# dmpac_targetdb register map
Vendor: Texas Instruments
Registers are 32-bit, read-write, no defined reset value unless marked. A register's access mark holds for its fields unless they carry their own. Offsets are as the file gives them; [hi:lo] are bit positions; {n}, {i} and the like mark numbered series; 'fields as' and 'values as' point back to an identical list.

## DMPAC (part 4 of 5) — Depth and Motion Perception Accelerator (DMPAC)
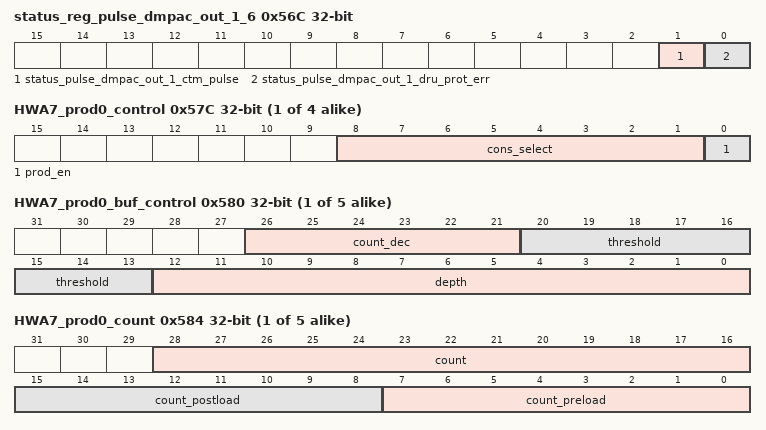
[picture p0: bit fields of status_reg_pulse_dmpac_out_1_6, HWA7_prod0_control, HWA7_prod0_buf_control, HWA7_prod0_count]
0x56C status_reg_pulse_dmpac_out_1_6 — Status Register 27
  [1] status_pulse_dmpac_out_1_ctm_pulse — Status ,write 1 to set, for pulse_dmpac_out_1_en_ctm_pulse
  [0] status_pulse_dmpac_out_1_dru_prot_err — Status ,write 1 to set, for pulse_dmpac_out_1_en_dru_prot_err
{0x57C+0x14*i} HWA7_prod{i}_control (i=0..3) — Controlling producer socket{i} for HWA7
  [8:1] cons_select — consumer select for HWA7 prod socket {i}. Used in decrementing count of producer buffer
  [0] prod_en — '1' -> Producer socket 0 enable , '0' Disable
{0x580+0x14*i} HWA7_prod{i}_buf_control (i=0..4) — Controlling producer socket{i} buffer for HWA7
  [26:21] count_dec — Count decrement value for prod count
  [20:13] threshold — Count threshold to generate pend for consumer
  [12:0] depth — Maximum number of producer buffer count
{0x584+0x14*i} HWA7_prod{i}_count access per field (i=0..4) — Defining count values for pre/post load for generating pend by HWA7 prod{i}
  [28:16] count ro — current count value
  [15:8] count_postload rw — count postload after producer max thread count reached
  [7:0] count_preload rw — count preload after scheduler start/init
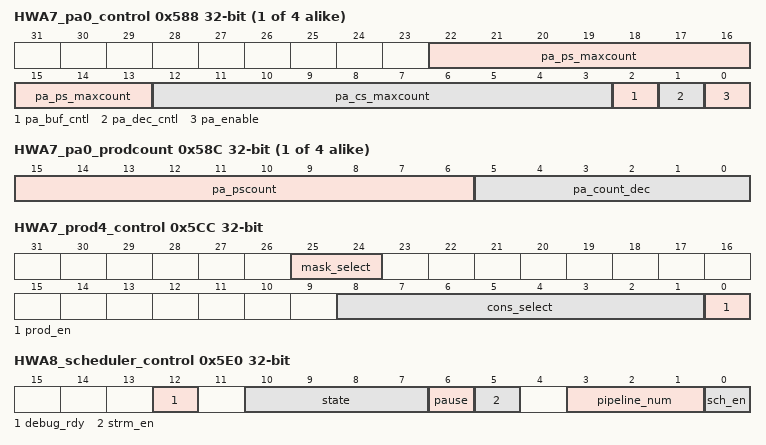
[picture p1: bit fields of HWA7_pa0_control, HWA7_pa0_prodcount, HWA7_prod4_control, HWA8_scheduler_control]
{0x588+0x14*i} HWA7_pa{i}_control (i=0..3) — control register to manage pattern adapter on HWA7 prod socket{i}
  [22:13] pa_ps_maxcount — destination count for pattern adaptation (N), M --> N
  [12:3] pa_cs_maxcount — source count for pattern adaptation (M), M --> N
  [2] pa_buf_cntl — '1' -> Apply threshold, count_preload and count_postload on pattern adapter count (use this only when pa_enable='1') '0' -> Apply threshold, count_preload and count_postload on prod count (same behavior as if no pattern adapter. Note when pa_enable='1' and pa_buf_cntl='0' threshold is not used and ignored)
  [1] pa_dec_cntl — '1' -> post pattern adaptation, decrement ps count by count_dec , '0' -> post pattern adaptation, decrement ps count by pa_cs_maxcount
  [0] pa_enable — '1' -> pa enable, '0' -> disable
{0x58C+0x14*i} HWA7_pa{i}_prodcount access per field (i=0..3) — count values for HWA7 prod socket{i}
  [15:6] pa_pscount ro — current count value of pa prod count
  [5:0] pa_count_dec rw — Decrement count value of pa_prod_count after pattern adapter prod count reaches threshold
0x5CC HWA7_prod4_control — Controlling producer socket4 for HWA7
  [25:24] mask_select — define which tdone_mask apply to prod socket 4. tdone_mask[mask_select] applies to prod_socket4
  [8:1] cons_select — consumer select for HWA7 prod socket 4. Used in decrementing count of producer buffer
  [0] prod_en — '1' -> Producer socket 0 enable , '0' Disable
0x5E0 HWA8_scheduler_control access per field — Scheduler Control Register
  [12] debug_rdy rw — '0' -> HWA8 Scheduler resources must not be read during halted state. '1'-> HWA8 Scheduler resources are readable during halted state
  [10:7] state ro — Current state of HWA8 Scheduler
  [6] pause rw — '1' -> pause/suspend scheduler , '0' -> resume scheduler
  [5] strm_en rw — '1' -> Streaming input enable, '0' No streaming input
  [3:1] pipeline_num rw — Pipeline Number of HWA8 Scheduler
  [0] sch_en rw — scheduler enable; write '1' to enable scheduler
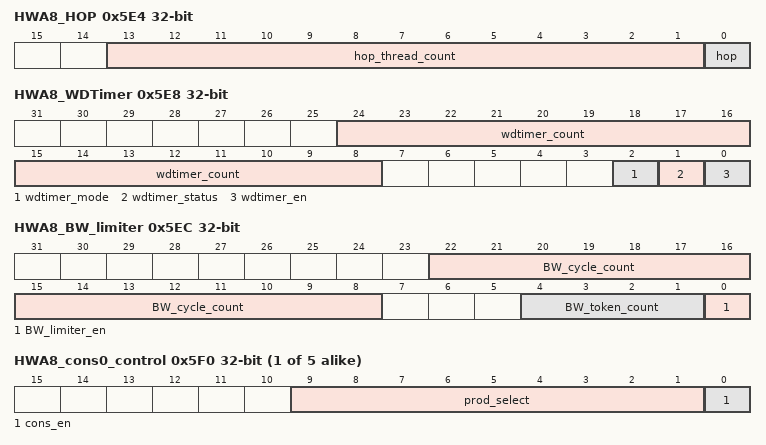
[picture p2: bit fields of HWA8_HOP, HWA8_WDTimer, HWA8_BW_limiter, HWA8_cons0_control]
0x5E4 HWA8_HOP — Scheduler HOP Control Register. Help in detecting eop within scheduler. Once configured, it counts task/channel starts and stops issuing further start. Specifically useful for Head of pipe dma scheduler .
  [13:1] hop_thread_count — Number of Task count for Head of pipe
  [0] hop — '1' -> Head of Pipe producer Sch , '0' -> No hop
0x5E8 HWA8_WDTimer access per field — Watchdog timer control register
  [24:8] wdtimer_count ro — Current value of HWA8 Scheduler watchdog timer count
  [2] wdtimer_mode rw — Watchdog timeout count '1' -> 128K , '0' -> 64K
  [1] wdtimer_status ro — HWA8 Scheduler watchdog timer status '1' -> Timer Active '0' -> Timer Inactive (count is stable)
  [0] wdtimer_en rw — '1' -> activate watchdog timer for 64K VPAC/DMPAC cycles between task start and task done '0' -> Disable watchdog timer
0x5EC HWA8_BW_limiter — Scheduler BW Control Register. Processing unit level BW control. Use DMA to eliminate peak system BW within processing units line/Block
  [22:8] BW_cycle_count — Average Cycle count between successive Task Start
  [4:1] BW_token_count — Max Token count to create average BW
  [0] BW_limiter_en — '1' -> Enable BW limiter function for HWA8 sch, '0' --> Disable
{0x5F0+4i} HWA8_cons{i}_control (i=0..4) — Controlling consumer socket {i} for HWA8
  [9:1] prod_select — producer select for HWA8 cons socket {i}
  [0] cons_en — '1' -> Consumer socket {i} enable , '0' Disable
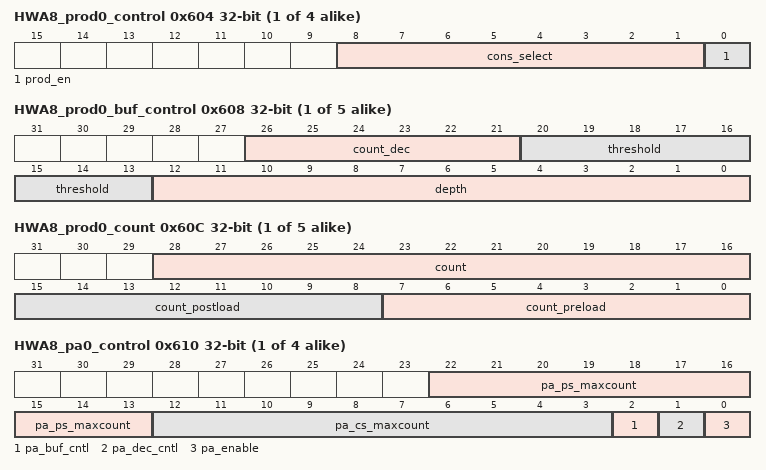
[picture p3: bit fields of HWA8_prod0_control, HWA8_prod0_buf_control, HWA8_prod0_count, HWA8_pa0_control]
{0x604+0x14*i} HWA8_prod{i}_control (i=0..3) — Controlling producer socket{i} for HWA8
  [8:1] cons_select — consumer select for HWA8 prod socket {i}. Used in decrementing count of producer buffer
  [0] prod_en — '1' -> Producer socket 0 enable , '0' Disable
{0x608+0x14*i} HWA8_prod{i}_buf_control (i=0..4) — Controlling producer socket{i} buffer for HWA8
  fields as HWA7_prod0_buf_control
{0x60C+0x14*i} HWA8_prod{i}_count access per field (i=0..4) — Defining count values for pre/post load for generating pend by HWA8 prod{i}
  fields as HWA7_prod0_count
{0x610+0x14*i} HWA8_pa{i}_control (i=0..3) — control register to manage pattern adapter on HWA8 prod socket{i}
  fields as HWA7_pa0_control
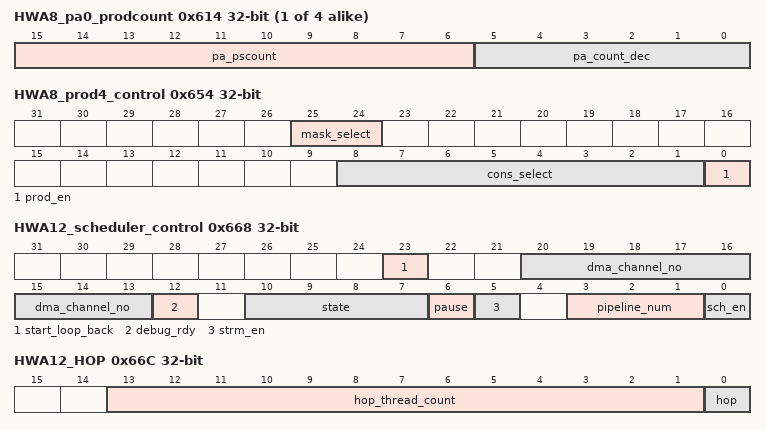
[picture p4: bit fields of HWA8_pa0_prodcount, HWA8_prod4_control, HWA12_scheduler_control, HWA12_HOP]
{0x614+0x14*i} HWA8_pa{i}_prodcount access per field (i=0..3) — count values for HWA8 prod socket{i}
  fields as HWA7_pa0_prodcount
0x654 HWA8_prod4_control — Controlling producer socket4 for HWA8
  [25:24] mask_select — define which tdone_mask apply to prod socket 4. tdone_mask[mask_select] applies to prod_socket4
  [8:1] cons_select — consumer select for HWA8 prod socket 4. Used in decrementing count of producer buffer
  [0] prod_en — '1' -> Producer socket 0 enable , '0' Disable
0x668 HWA12_scheduler_control access per field — Scheduler Control Register
  [23] start_loop_back rw — '1' -> loop back start onto done in same cycle w/o asserting external channel start, '0' No loop back
  [20:13] dma_channel_no rw — DMA channel number for thread scheduler for HWA12
  [12] debug_rdy rw — '0' -> HWA12 Scheduler resources must not be read during halted state. '1'-> HWA12 Scheduler resources are readable during halted state
  [10:7] state ro — Current state of HWA12 Scheduler
  [6] pause rw — '1' -> pause/suspend scheduler , '0' -> resume scheduler
  [5] strm_en rw — '1' -> Streaming input enable, '0' No streaming input
  [3:1] pipeline_num rw — Pipeline Number of HWA12 Scheduler
  [0] sch_en rw — scheduler enable; write '1' to enable scheduler
0x66C HWA12_HOP — Scheduler HOP Control Register. Help in detecting eop within scheduler. Once configured, it counts task/channel starts and stops issuing further starts. Specifically useful for Head of pipe dma scheduler .
  fields as HWA8_HOP
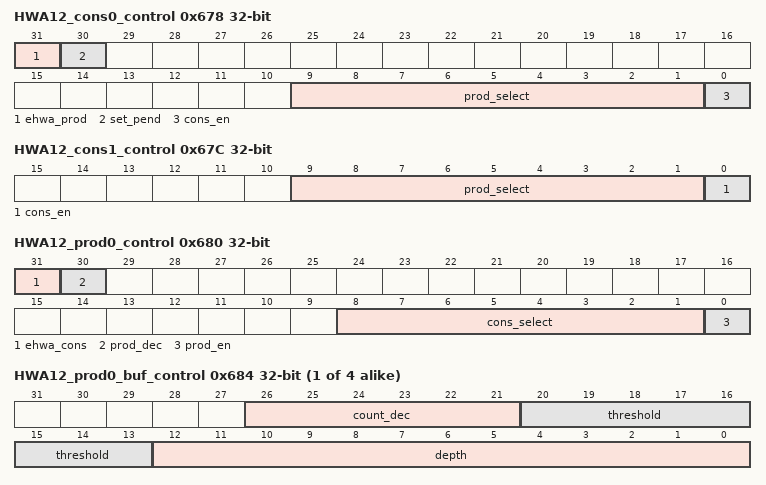
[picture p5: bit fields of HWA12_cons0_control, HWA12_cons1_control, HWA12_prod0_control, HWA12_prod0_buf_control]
0x678 HWA12_cons0_control access per field — Controlling consumer socket 0 for HWA12
  [31] ehwa_prod rw — '1' -> spare consumer is connected to external host producer , '0' --> no external host producer
  [30] set_pend wo — writing '1' sets pend on consumer socket
  [9:1] prod_select rw — producer select for HWA12 cons socket 0
  [0] cons_en rw — '1' -> Consumer socket 0 enable , '0' Disable
0x67C HWA12_cons1_control — Controlling consumer socket 1 for HWA12
  [9:1] prod_select — producer select for HWA12 cons socket 1
  [0] cons_en — '1' -> Consumer socket 1 enable , '0' Disable
0x680 HWA12_prod0_control access per field — Controlling producer socket0 for HWA12
  [31] ehwa_cons rw — '1' -> spare consumer is connected to external host consumer , '0' --> no external host consumer
  [30] prod_dec wo — writing '1' decrement prod count value
  [8:1] cons_select rw — consumer select for HWA12 prod socket 0. Used in decrementing count of producer buffer
  [0] prod_en rw — '1' -> Producer socket 0 enable , '0' Disable
{0x684+0x14*i} HWA12_prod{i}_buf_control (i=0..3) — Controlling producer socket{i} buffer for HWA12
  fields as HWA7_prod0_buf_control
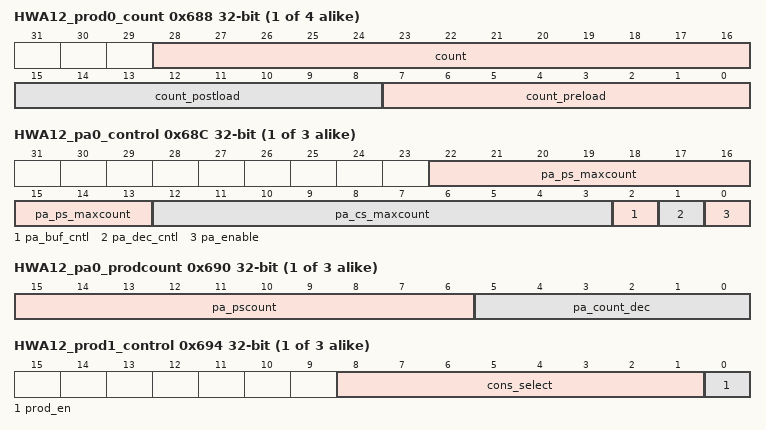
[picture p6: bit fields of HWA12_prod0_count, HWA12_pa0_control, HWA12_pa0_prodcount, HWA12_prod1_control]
{0x688+0x14*i} HWA12_prod{i}_count access per field (i=0..3) — Defining count values for pre/post load for generating pend by HWA12 prod{i}
  fields as HWA7_prod0_count
{0x68C+0x14*i} HWA12_pa{i}_control (i=0..2) — control register to manage pattern adapter on HWA12 prod socket{i}
  fields as HWA7_pa0_control
{0x690+0x14*i} HWA12_pa{i}_prodcount access per field (i=0..2) — count values for HWA12 prod socket{i}
  fields as HWA7_pa0_prodcount
{0x680+0x14*i} HWA12_prod{i}_control (i=1..3) — Controlling producer socket{i} for HWA12
  [8:1] cons_select — consumer select for HWA12 prod socket {i}. Used in decrementing count of producer buffer
  [0] prod_en — '1' -> Producer socket 0 enable , '0' Disable
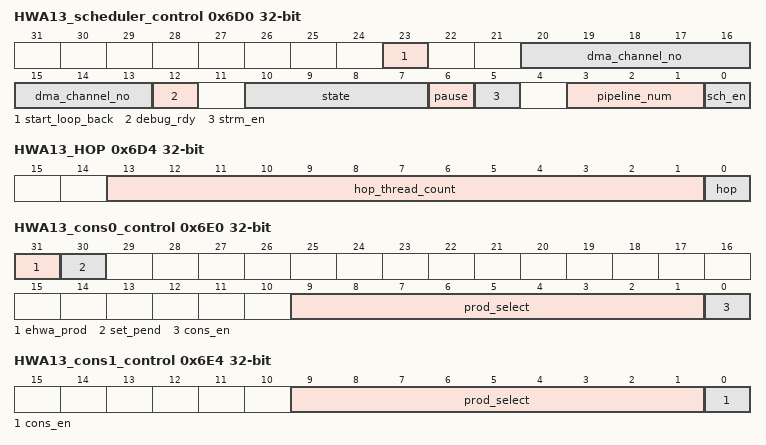
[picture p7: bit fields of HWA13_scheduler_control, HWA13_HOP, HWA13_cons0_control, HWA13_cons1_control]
0x6D0 HWA13_scheduler_control access per field — Scheduler Control Register
  [23] start_loop_back rw — '1' -> loop back start onto done in same cycle w/o asserting external channel start, '0' No loop back
  [20:13] dma_channel_no rw — DMA channel number for thread scheduler for HWA13
  [12] debug_rdy rw — '0' -> HWA13 Scheduler resources must not be read during halted state. '1'-> HWA13 Scheduler resources are readable during halted state
  [10:7] state ro — Current state of HWA13 Scheduler
  [6] pause rw — '1' -> pause/suspend scheduler , '0' -> resume scheduler
  [5] strm_en rw — '1' -> Streaming input enable, '0' No streaming input
  [3:1] pipeline_num rw — Pipeline Number of HWA13 Scheduler
  [0] sch_en rw — scheduler enable; write '1' to enable scheduler
0x6D4 HWA13_HOP — Scheduler HOP Control Register. Help in detecting eop within scheduler. Once configured, it counts task/channel starts and stops issuing further starts. Specifically useful for Head of pipe dma scheduler .
  fields as HWA8_HOP
0x6E0 HWA13_cons0_control access per field — Controlling consumer socket 0 for HWA13
  [31] ehwa_prod rw — '1' -> spare consumer is connected to external host producer , '0' --> no external host producer
  [30] set_pend wo — writing '1' sets pend on consumer socket
  [9:1] prod_select rw — producer select for HWA13 cons socket 0
  [0] cons_en rw — '1' -> Consumer socket 0 enable , '0' Disable
0x6E4 HWA13_cons1_control — Controlling consumer socket 1 for HWA13
  [9:1] prod_select — producer select for HWA13 cons socket 1
  [0] cons_en — '1' -> Consumer socket 1 enable , '0' Disable
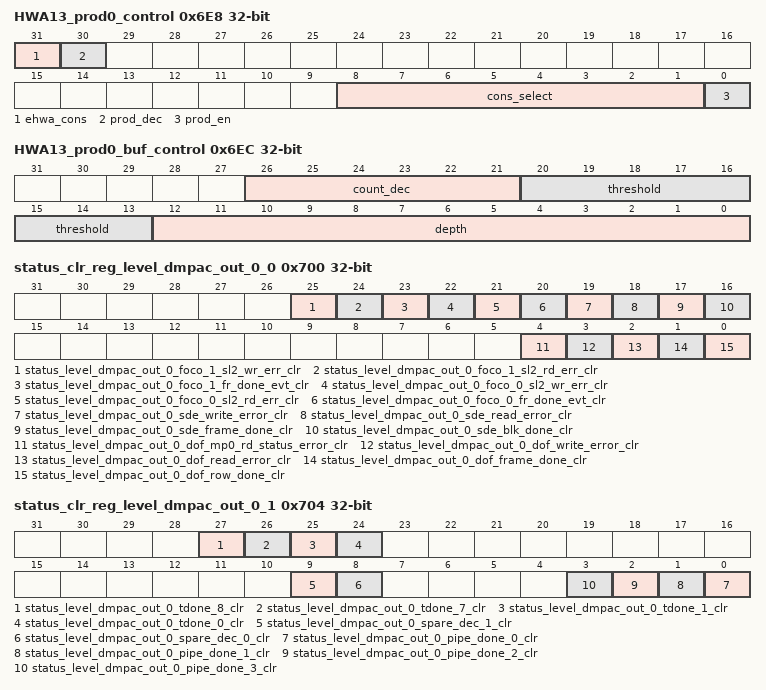
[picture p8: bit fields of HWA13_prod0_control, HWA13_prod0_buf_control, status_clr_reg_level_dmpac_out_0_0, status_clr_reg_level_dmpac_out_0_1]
0x6E8 HWA13_prod0_control access per field — Controlling producer socket0 for HWA13
  [31] ehwa_cons rw — '1' -> spare consumer is connected to external host consumer , '0' --> no external host consumer
  [30] prod_dec wo — writing '1' decrement prod count value
  [8:1] cons_select rw — consumer select for HWA13 prod socket 0. Used in decrementing count of producer buffer
  [0] prod_en rw — '1' -> Producer socket 0 enable , '0' Disable
0x6EC HWA13_prod0_buf_control — Controlling producer socket0 buffer for HWA13
  fields as HWA7_prod0_buf_control
0x6F0 HWA13_prod0_count access per field — Defining count values for pre/post load for generating pend by HWA13 prod0
  [16:13] count ro — current count value
  [15:8] count_postload rw — count postload after producer max thread count reached
  [7:0] count_preload rw — count preload after scheduler start/init
{0x1AC+0x68*i} HWA{i}_pa0_control (i=13..19) — control register to manage pattern adapter on HWA{i} prod socket0
  [13:10] pa_ps_maxcount — destination count for pattern adaptation (N), M --> N
  [10:3] pa_cs_maxcount — source count for pattern adaptation (M), M --> N
  [1] pa_dec_cntl — '1' -> post pattern adaptation, decrement ps count by count_dec , '0' -> post pattern adaptation, decrement ps count by pa_cs_maxcount
  [2:1] pa_buf_cntl — '1' -> Apply threshold, count_preload and count_postload on pattern adapter count (use this only when pa_enable='1') '0' -> Apply threshold, count_preload and count_postload on prod count (same behavior as if no pattern adapter. Note when pa_enable='1' and pa_buf_cntl='0' threshold is not used and ignored)
  [1:0] pa_enable — '1' -> pa enable, '0' -> disable
{0x6F8+0x14*i} HWA13_pa{i}_prodcount access per field (i=0..2) — count values for HWA13 prod socket{i}
  [10:6] pa_pscount ro — current count value of pa prod count
  [6:0] pa_count_dec rw — Decrement count value of pa_prod_count after pattern adapter prod count reaches threshold
{0x1B4+0x68*i} HWA{i}_prod1_control (i=13..19) — Controlling producer socket1 for HWA{i}
  [8:1] cons_select — consumer select for HWA{i} prod socket 1. Used in decrementing count of producer buffer
  [1:0] prod_en — '1' -> Producer socket 0 enable , '0' Disable
0x700 status_clr_reg_level_dmpac_out_0_0 — Status Clear Register 0
  [25] status_level_dmpac_out_0_foco_1_sl2_wr_err_clr — Status ,write 1 to clear, for level_dmpac_out_0_en_foco_1_sl2_wr_err
  [24] status_level_dmpac_out_0_foco_1_sl2_rd_err_clr — Status ,write 1 to clear, for level_dmpac_out_0_en_foco_1_sl2_rd_err
  [23] status_level_dmpac_out_0_foco_1_fr_done_evt_clr — Status ,write 1 to clear, for level_dmpac_out_0_en_foco_1_fr_done_evt
  [22] status_level_dmpac_out_0_foco_0_sl2_wr_err_clr — Status ,write 1 to clear, for level_dmpac_out_0_en_foco_0_sl2_wr_err
  [21] status_level_dmpac_out_0_foco_0_sl2_rd_err_clr — Status ,write 1 to clear, for level_dmpac_out_0_en_foco_0_sl2_rd_err
  [20] status_level_dmpac_out_0_foco_0_fr_done_evt_clr — Status ,write 1 to clear, for level_dmpac_out_0_en_foco_0_fr_done_evt
  [19] status_level_dmpac_out_0_sde_write_error_clr — Status ,write 1 to clear, for level_dmpac_out_0_en_sde_write_error
  [18] status_level_dmpac_out_0_sde_read_error_clr — Status ,write 1 to clear, for level_dmpac_out_0_en_sde_read_error
  [17] status_level_dmpac_out_0_sde_frame_done_clr — Status ,write 1 to clear, for level_dmpac_out_0_en_sde_frame_done
  [16] status_level_dmpac_out_0_sde_blk_done_clr — Status ,write 1 to clear, for level_dmpac_out_0_en_sde_blk_done
  [4] status_level_dmpac_out_0_dof_mp0_rd_status_error_clr — Status ,write 1 to clear, for level_dmpac_out_0_en_dof_mp0_rd_status_error
  [3] status_level_dmpac_out_0_dof_write_error_clr — Status ,write 1 to clear, for level_dmpac_out_0_en_dof_write_error
  [2] status_level_dmpac_out_0_dof_read_error_clr — Status ,write 1 to clear, for level_dmpac_out_0_en_dof_read_error
  [1] status_level_dmpac_out_0_dof_frame_done_clr — Status ,write 1 to clear, for level_dmpac_out_0_en_dof_frame_done
  [0] status_level_dmpac_out_0_dof_row_done_clr — Status ,write 1 to clear, for level_dmpac_out_0_en_dof_row_done
{0x1B8+0x68*i} HWA{i}_prod1_buf_control (i=13..19) — Controlling producer socket1 buffer for HWA{i}
  [13:8] threshold — Count threshold to generate pend for consumer
  [21:6] count_dec — Count decrement value for prod count
  [13:0] depth — Maximum number of producer buffer count
0x704 status_clr_reg_level_dmpac_out_0_1 — Status Clear Register 1
  [27] status_level_dmpac_out_0_tdone_8_clr — Status ,write 1 to clear, for level_dmpac_out_0_en_tdone_8
  [26] status_level_dmpac_out_0_tdone_7_clr — Status ,write 1 to clear, for level_dmpac_out_0_en_tdone_7
  [25] status_level_dmpac_out_0_tdone_1_clr — Status ,write 1 to clear, for level_dmpac_out_0_en_tdone_1
  [24] status_level_dmpac_out_0_tdone_0_clr — Status ,write 1 to clear, for level_dmpac_out_0_en_tdone_0
  [9] status_level_dmpac_out_0_spare_dec_1_clr — Status ,write 1 to clear, for level_dmpac_out_0_en_spare_dec_1
  [8] status_level_dmpac_out_0_spare_dec_0_clr — Status ,write 1 to clear, for level_dmpac_out_0_en_spare_dec_0
  [n] status_level_dmpac_out_0_pipe_done_{n}_clr (n=0..3) — Status ,write 1 to clear, for level_dmpac_out_0_en_pipe_done_{n}
{0x1BC+0x68*i} HWA{i}_prod1_count access per field (i=13..19) — Defining count values for pre/post load for generating pend by HWA{i} prod1
  [16:13] count ro — current count value
  [8] count_postload rw — count postload after producer max thread count reached
  [8:0] count_preload rw — count preload after scheduler start/init
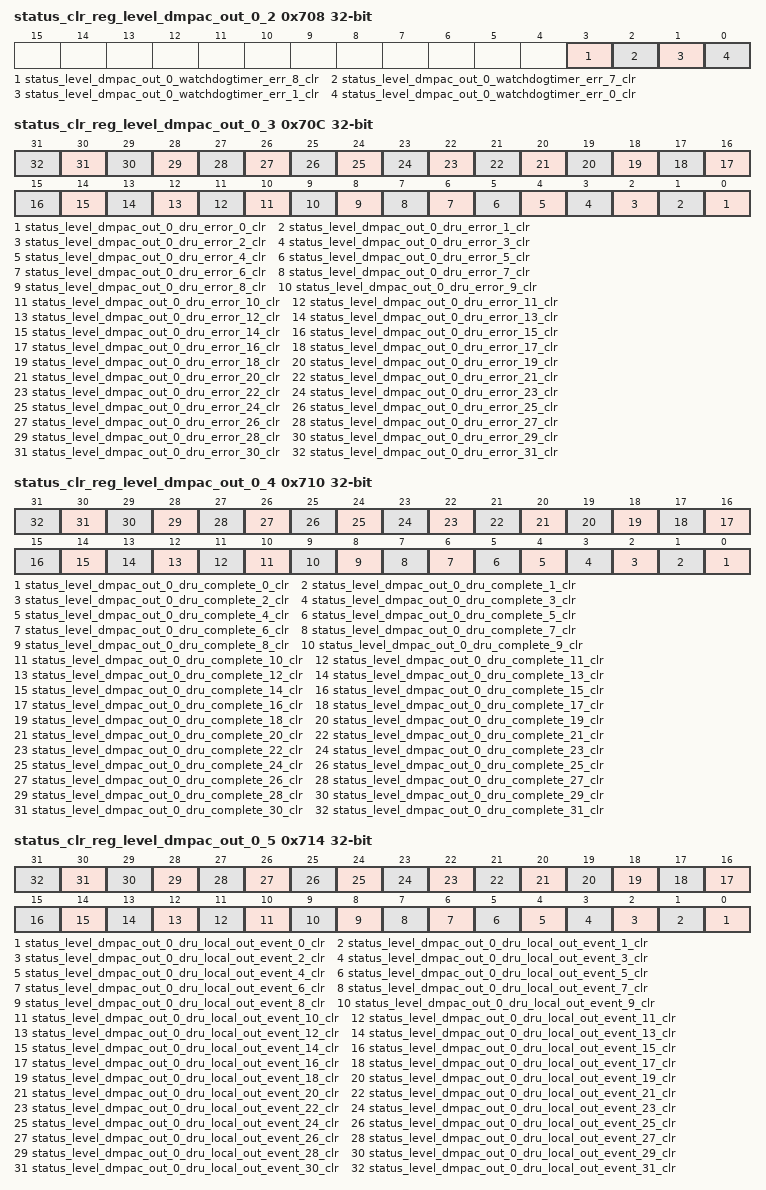
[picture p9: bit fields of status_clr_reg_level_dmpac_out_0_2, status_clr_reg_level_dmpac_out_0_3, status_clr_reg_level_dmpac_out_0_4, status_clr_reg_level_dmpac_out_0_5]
0x708 status_clr_reg_level_dmpac_out_0_2 — Status Clear Register 2
  [3] status_level_dmpac_out_0_watchdogtimer_err_8_clr — Status ,write 1 to clear, for level_dmpac_out_0_en_watchdogtimer_err_8
  [2] status_level_dmpac_out_0_watchdogtimer_err_7_clr — Status ,write 1 to clear, for level_dmpac_out_0_en_watchdogtimer_err_7
  [1] status_level_dmpac_out_0_watchdogtimer_err_1_clr — Status ,write 1 to clear, for level_dmpac_out_0_en_watchdogtimer_err_1
  [0] status_level_dmpac_out_0_watchdogtimer_err_0_clr — Status ,write 1 to clear, for level_dmpac_out_0_en_watchdogtimer_err_0
{0x1C0+0x68*i} HWA{i}_pa1_control (i=13..19) — control register to manage pattern adapter on HWA{i} prod socket1
  fields as HWA13_pa0_control
0x70C status_clr_reg_level_dmpac_out_0_3 — Status Clear Register 3
  [n] status_level_dmpac_out_0_dru_error_{n}_clr (n=0..31) — Status ,write 1 to clear, for level_dmpac_out_0_en_dru_error_{n}
0x710 status_clr_reg_level_dmpac_out_0_4 — Status Clear Register 4
  [n] status_level_dmpac_out_0_dru_complete_{n}_clr (n=0..31) — Status ,write 1 to clear, for level_dmpac_out_0_en_dru_complete_{n}
{0x1C8+0x68*i} HWA{i}_prod2_control (i=13..19) — Controlling producer socket2 for HWA{i}
  [8:1] cons_select — consumer select for HWA{i} prod socket 2. Used in decrementing count of producer buffer
  [1:0] prod_en — '1' -> Producer socket 0 enable , '0' Disable
0x714 status_clr_reg_level_dmpac_out_0_5 — Status Clear Register 5
  [n] status_level_dmpac_out_0_dru_local_out_event_{n}_clr (n=0..31) — Status ,write 1 to clear, for level_dmpac_out_0_en_dru_local_out_event_{n}
{0x1CC+0x68*i} HWA{i}_prod2_buf_control (i=13..19) — Controlling producer socket2 buffer for HWA{i}
  fields as HWA13_prod1_buf_control
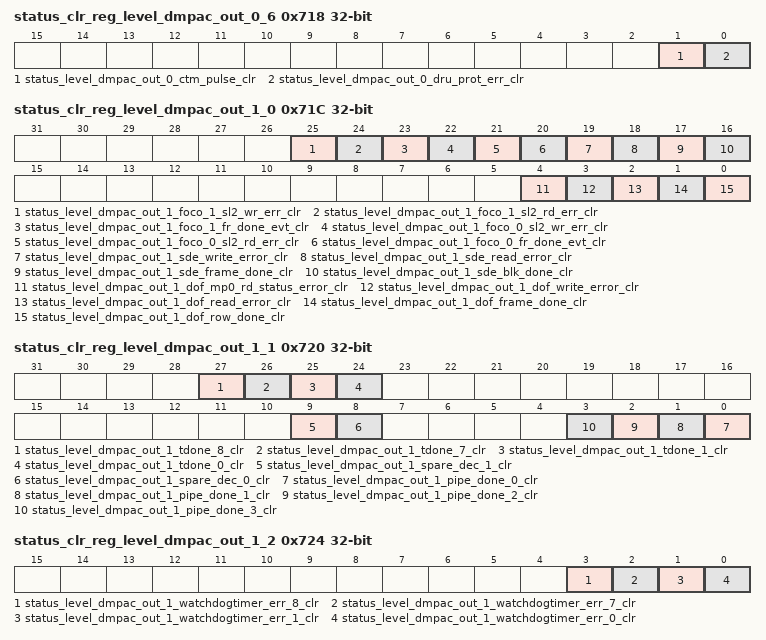
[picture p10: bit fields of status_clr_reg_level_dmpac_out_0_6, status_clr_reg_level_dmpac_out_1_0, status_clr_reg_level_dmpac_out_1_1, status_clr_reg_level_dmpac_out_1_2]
0x718 status_clr_reg_level_dmpac_out_0_6 — Status Clear Register 6
  [1] status_level_dmpac_out_0_ctm_pulse_clr — Status ,write 1 to clear, for level_dmpac_out_0_en_ctm_pulse
  [0] status_level_dmpac_out_0_dru_prot_err_clr — Status ,write 1 to clear, for level_dmpac_out_0_en_dru_prot_err
{0x1D0+0x68*i} HWA{i}_prod2_count access per field (i=13..19) — Defining count values for pre/post load for generating pend by HWA{i} prod2
  fields as HWA13_prod1_count
0x71C status_clr_reg_level_dmpac_out_1_0 — Status Clear Register 7
  [25] status_level_dmpac_out_1_foco_1_sl2_wr_err_clr — Status ,write 1 to clear, for level_dmpac_out_1_en_foco_1_sl2_wr_err
  [24] status_level_dmpac_out_1_foco_1_sl2_rd_err_clr — Status ,write 1 to clear, for level_dmpac_out_1_en_foco_1_sl2_rd_err
  [23] status_level_dmpac_out_1_foco_1_fr_done_evt_clr — Status ,write 1 to clear, for level_dmpac_out_1_en_foco_1_fr_done_evt
  [22] status_level_dmpac_out_1_foco_0_sl2_wr_err_clr — Status ,write 1 to clear, for level_dmpac_out_1_en_foco_0_sl2_wr_err
  [21] status_level_dmpac_out_1_foco_0_sl2_rd_err_clr — Status ,write 1 to clear, for level_dmpac_out_1_en_foco_0_sl2_rd_err
  [20] status_level_dmpac_out_1_foco_0_fr_done_evt_clr — Status ,write 1 to clear, for level_dmpac_out_1_en_foco_0_fr_done_evt
  [19] status_level_dmpac_out_1_sde_write_error_clr — Status ,write 1 to clear, for level_dmpac_out_1_en_sde_write_error
  [18] status_level_dmpac_out_1_sde_read_error_clr — Status ,write 1 to clear, for level_dmpac_out_1_en_sde_read_error
  [17] status_level_dmpac_out_1_sde_frame_done_clr — Status ,write 1 to clear, for level_dmpac_out_1_en_sde_frame_done
  [16] status_level_dmpac_out_1_sde_blk_done_clr — Status ,write 1 to clear, for level_dmpac_out_1_en_sde_blk_done
  [4] status_level_dmpac_out_1_dof_mp0_rd_status_error_clr — Status ,write 1 to clear, for level_dmpac_out_1_en_dof_mp0_rd_status_error
  [3] status_level_dmpac_out_1_dof_write_error_clr — Status ,write 1 to clear, for level_dmpac_out_1_en_dof_write_error
  [2] status_level_dmpac_out_1_dof_read_error_clr — Status ,write 1 to clear, for level_dmpac_out_1_en_dof_read_error
  [1] status_level_dmpac_out_1_dof_frame_done_clr — Status ,write 1 to clear, for level_dmpac_out_1_en_dof_frame_done
  [0] status_level_dmpac_out_1_dof_row_done_clr — Status ,write 1 to clear, for level_dmpac_out_1_en_dof_row_done
{0x1D4+0x68*i} HWA{i}_pa2_control (i=13..19) — control register to manage pattern adapter on HWA{i} prod socket2
  fields as HWA13_pa0_control
0x720 status_clr_reg_level_dmpac_out_1_1 — Status Clear Register 8
  [27] status_level_dmpac_out_1_tdone_8_clr — Status ,write 1 to clear, for level_dmpac_out_1_en_tdone_8
  [26] status_level_dmpac_out_1_tdone_7_clr — Status ,write 1 to clear, for level_dmpac_out_1_en_tdone_7
  [25] status_level_dmpac_out_1_tdone_1_clr — Status ,write 1 to clear, for level_dmpac_out_1_en_tdone_1
  [24] status_level_dmpac_out_1_tdone_0_clr — Status ,write 1 to clear, for level_dmpac_out_1_en_tdone_0
  [9] status_level_dmpac_out_1_spare_dec_1_clr — Status ,write 1 to clear, for level_dmpac_out_1_en_spare_dec_1
  [8] status_level_dmpac_out_1_spare_dec_0_clr — Status ,write 1 to clear, for level_dmpac_out_1_en_spare_dec_0
  [n] status_level_dmpac_out_1_pipe_done_{n}_clr (n=0..3) — Status ,write 1 to clear, for level_dmpac_out_1_en_pipe_done_{n}
0x724 status_clr_reg_level_dmpac_out_1_2 — Status Clear Register 9
  [3] status_level_dmpac_out_1_watchdogtimer_err_8_clr — Status ,write 1 to clear, for level_dmpac_out_1_en_watchdogtimer_err_8
  [2] status_level_dmpac_out_1_watchdogtimer_err_7_clr — Status ,write 1 to clear, for level_dmpac_out_1_en_watchdogtimer_err_7
  [1] status_level_dmpac_out_1_watchdogtimer_err_1_clr — Status ,write 1 to clear, for level_dmpac_out_1_en_watchdogtimer_err_1
  [0] status_level_dmpac_out_1_watchdogtimer_err_0_clr — Status ,write 1 to clear, for level_dmpac_out_1_en_watchdogtimer_err_0
{0x1DC+0x68*i} HWA{i}_prod3_control (i=13..19) — Controlling producer socket3 for HWA{i}
  [8:1] cons_select — consumer select for HWA{i} prod socket 3. Used in decrementing count of producer buffer
  [1:0] prod_en — '1' -> Producer socket 0 enable , '0' Disable
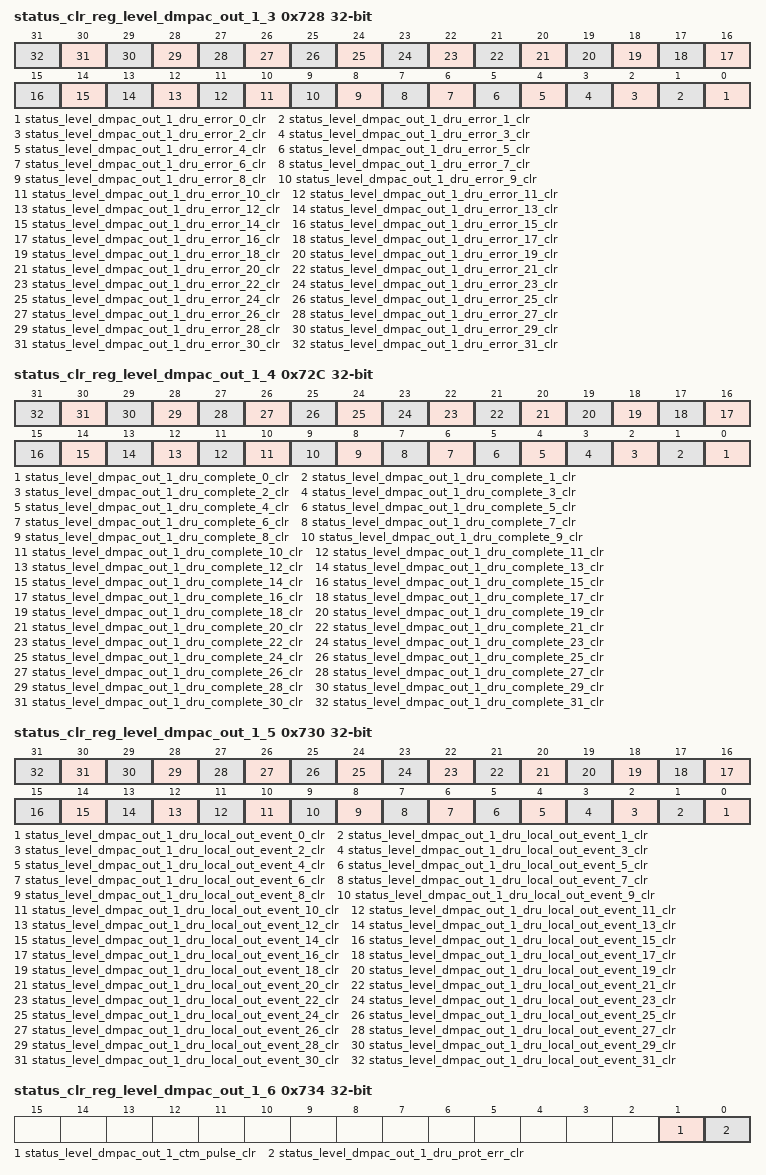
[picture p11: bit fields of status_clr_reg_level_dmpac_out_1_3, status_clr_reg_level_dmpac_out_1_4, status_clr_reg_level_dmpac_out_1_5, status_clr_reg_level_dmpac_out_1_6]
0x728 status_clr_reg_level_dmpac_out_1_3 — Status Clear Register 10
  [n] status_level_dmpac_out_1_dru_error_{n}_clr (n=0..31) — Status ,write 1 to clear, for level_dmpac_out_1_en_dru_error_{n}
{0x1E0+0x68*i} HWA{i}_prod3_buf_control (i=13..19) — Controlling producer socket3 buffer for HWA{i}
  fields as HWA13_prod1_buf_control
0x72C status_clr_reg_level_dmpac_out_1_4 — Status Clear Register 11
  [n] status_level_dmpac_out_1_dru_complete_{n}_clr (n=0..31) — Status ,write 1 to clear, for level_dmpac_out_1_en_dru_complete_{n}
{0x1E4+0x68*i} HWA{i}_prod3_count access per field (i=13..19) — Defining count values for pre/post load for generating pend by HWA{i} prod3
  fields as HWA13_prod1_count
0x730 status_clr_reg_level_dmpac_out_1_5 — Status Clear Register 12
  [n] status_level_dmpac_out_1_dru_local_out_event_{n}_clr (n=0..31) — Status ,write 1 to clear, for level_dmpac_out_1_en_dru_local_out_event_{n}
0x734 status_clr_reg_level_dmpac_out_1_6 — Status Clear Register 13
  [1] status_level_dmpac_out_1_ctm_pulse_clr — Status ,write 1 to clear, for level_dmpac_out_1_en_ctm_pulse
  [0] status_level_dmpac_out_1_dru_prot_err_clr — Status ,write 1 to clear, for level_dmpac_out_1_en_dru_prot_err
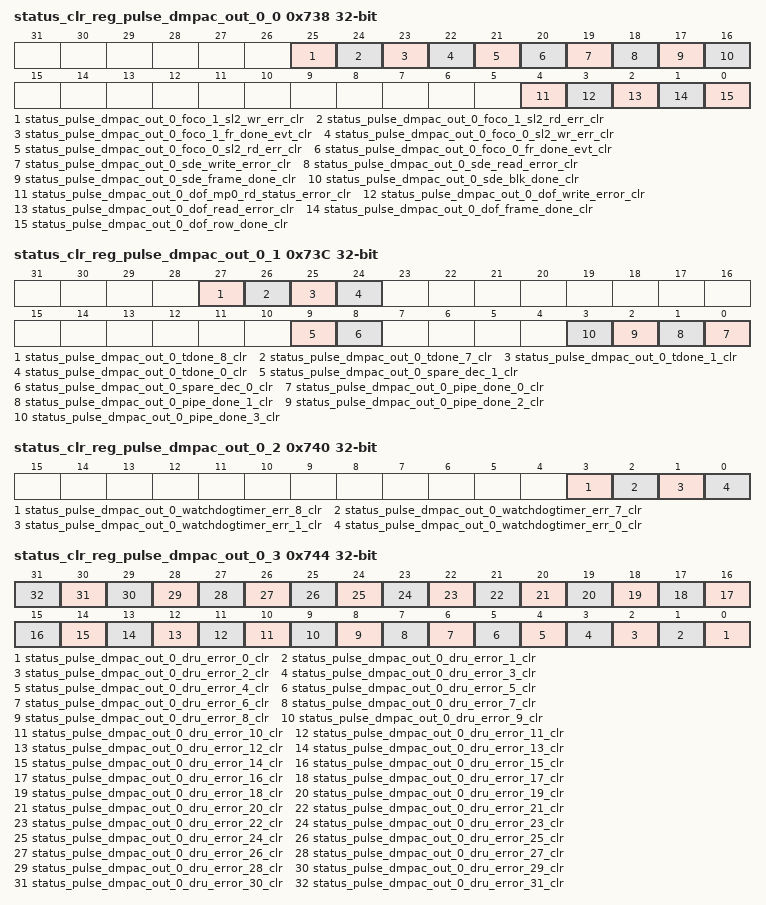
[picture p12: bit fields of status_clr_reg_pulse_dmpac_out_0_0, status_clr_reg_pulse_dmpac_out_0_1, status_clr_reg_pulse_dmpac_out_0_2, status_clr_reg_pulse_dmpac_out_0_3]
0x738 status_clr_reg_pulse_dmpac_out_0_0 — Status Clear Register 14
  [25] status_pulse_dmpac_out_0_foco_1_sl2_wr_err_clr — Status ,write 1 to clear, for pulse_dmpac_out_0_en_foco_1_sl2_wr_err
  [24] status_pulse_dmpac_out_0_foco_1_sl2_rd_err_clr — Status ,write 1 to clear, for pulse_dmpac_out_0_en_foco_1_sl2_rd_err
  [23] status_pulse_dmpac_out_0_foco_1_fr_done_evt_clr — Status ,write 1 to clear, for pulse_dmpac_out_0_en_foco_1_fr_done_evt
  [22] status_pulse_dmpac_out_0_foco_0_sl2_wr_err_clr — Status ,write 1 to clear, for pulse_dmpac_out_0_en_foco_0_sl2_wr_err
  [21] status_pulse_dmpac_out_0_foco_0_sl2_rd_err_clr — Status ,write 1 to clear, for pulse_dmpac_out_0_en_foco_0_sl2_rd_err
  [20] status_pulse_dmpac_out_0_foco_0_fr_done_evt_clr — Status ,write 1 to clear, for pulse_dmpac_out_0_en_foco_0_fr_done_evt
  [19] status_pulse_dmpac_out_0_sde_write_error_clr — Status ,write 1 to clear, for pulse_dmpac_out_0_en_sde_write_error
  [18] status_pulse_dmpac_out_0_sde_read_error_clr — Status ,write 1 to clear, for pulse_dmpac_out_0_en_sde_read_error
  [17] status_pulse_dmpac_out_0_sde_frame_done_clr — Status ,write 1 to clear, for pulse_dmpac_out_0_en_sde_frame_done
  [16] status_pulse_dmpac_out_0_sde_blk_done_clr — Status ,write 1 to clear, for pulse_dmpac_out_0_en_sde_blk_done
  [4] status_pulse_dmpac_out_0_dof_mp0_rd_status_error_clr — Status ,write 1 to clear, for pulse_dmpac_out_0_en_dof_mp0_rd_status_error
  [3] status_pulse_dmpac_out_0_dof_write_error_clr — Status ,write 1 to clear, for pulse_dmpac_out_0_en_dof_write_error
  [2] status_pulse_dmpac_out_0_dof_read_error_clr — Status ,write 1 to clear, for pulse_dmpac_out_0_en_dof_read_error
  [1] status_pulse_dmpac_out_0_dof_frame_done_clr — Status ,write 1 to clear, for pulse_dmpac_out_0_en_dof_frame_done
  [0] status_pulse_dmpac_out_0_dof_row_done_clr — Status ,write 1 to clear, for pulse_dmpac_out_0_en_dof_row_done
{0x188+0x68*i} HWA{i}_scheduler_control access per field (i=14..19) — Scheduler Control Register
  [13:8] dma_channel_no rw — DMA channel number for thread scheduler for HWA{i}
  [7:4] state ro — Current state of HWA{i} Scheduler
  [3:1] pipeline_num rw — Pipeline Number of HWA{i} Scheduler
  [5:1] strm_en rw — '1' -> Streaming input enable, '0' No streaming input
  [6:1] pause rw — '1' -> pause/suspend scheduler , '0' -> resume scheduler
  [12:1] debug_rdy rw — '0' -> HWA{i} Scheduler resources must not be read during halted state. '1'-> HWA{i} Scheduler resources are readable during halted state
  [23:1] start_loop_back rw — '1' -> loop back start onto done in same cycle w/o asserting external channel start, '0' No loop back
  [1:0] sch_en rw — scheduler enable; write '1' to enable scheduler
0x73C status_clr_reg_pulse_dmpac_out_0_1 — Status Clear Register 15
  [27] status_pulse_dmpac_out_0_tdone_8_clr — Status ,write 1 to clear, for pulse_dmpac_out_0_en_tdone_8
  [26] status_pulse_dmpac_out_0_tdone_7_clr — Status ,write 1 to clear, for pulse_dmpac_out_0_en_tdone_7
  [25] status_pulse_dmpac_out_0_tdone_1_clr — Status ,write 1 to clear, for pulse_dmpac_out_0_en_tdone_1
  [24] status_pulse_dmpac_out_0_tdone_0_clr — Status ,write 1 to clear, for pulse_dmpac_out_0_en_tdone_0
  [9] status_pulse_dmpac_out_0_spare_dec_1_clr — Status ,write 1 to clear, for pulse_dmpac_out_0_en_spare_dec_1
  [8] status_pulse_dmpac_out_0_spare_dec_0_clr — Status ,write 1 to clear, for pulse_dmpac_out_0_en_spare_dec_0
  [n] status_pulse_dmpac_out_0_pipe_done_{n}_clr (n=0..3) — Status ,write 1 to clear, for pulse_dmpac_out_0_en_pipe_done_{n}
{0x18C+0x68*i} HWA{i}_HOP (i=14..19) — Scheduler HOP Control Register. Help in detecting eop within scheduler. Once configured, it counts task/channel starts and stops issuing further starts. Specifically useful for Head of pipe dma scheduler .
  [13:1] hop_thread_count — Number of Task count for Head of pipe
  [1:0] hop — '1' -> Head of Pipe producer Sch , '0' -> No hop
0x740 status_clr_reg_pulse_dmpac_out_0_2 — Status Clear Register 16
  [3] status_pulse_dmpac_out_0_watchdogtimer_err_8_clr — Status ,write 1 to clear, for pulse_dmpac_out_0_en_watchdogtimer_err_8
  [2] status_pulse_dmpac_out_0_watchdogtimer_err_7_clr — Status ,write 1 to clear, for pulse_dmpac_out_0_en_watchdogtimer_err_7
  [1] status_pulse_dmpac_out_0_watchdogtimer_err_1_clr — Status ,write 1 to clear, for pulse_dmpac_out_0_en_watchdogtimer_err_1
  [0] status_pulse_dmpac_out_0_watchdogtimer_err_0_clr — Status ,write 1 to clear, for pulse_dmpac_out_0_en_watchdogtimer_err_0
0x744 status_clr_reg_pulse_dmpac_out_0_3 — Status Clear Register 17
  [n] status_pulse_dmpac_out_0_dru_error_{n}_clr (n=0..31) — Status ,write 1 to clear, for pulse_dmpac_out_0_en_dru_error_{n}
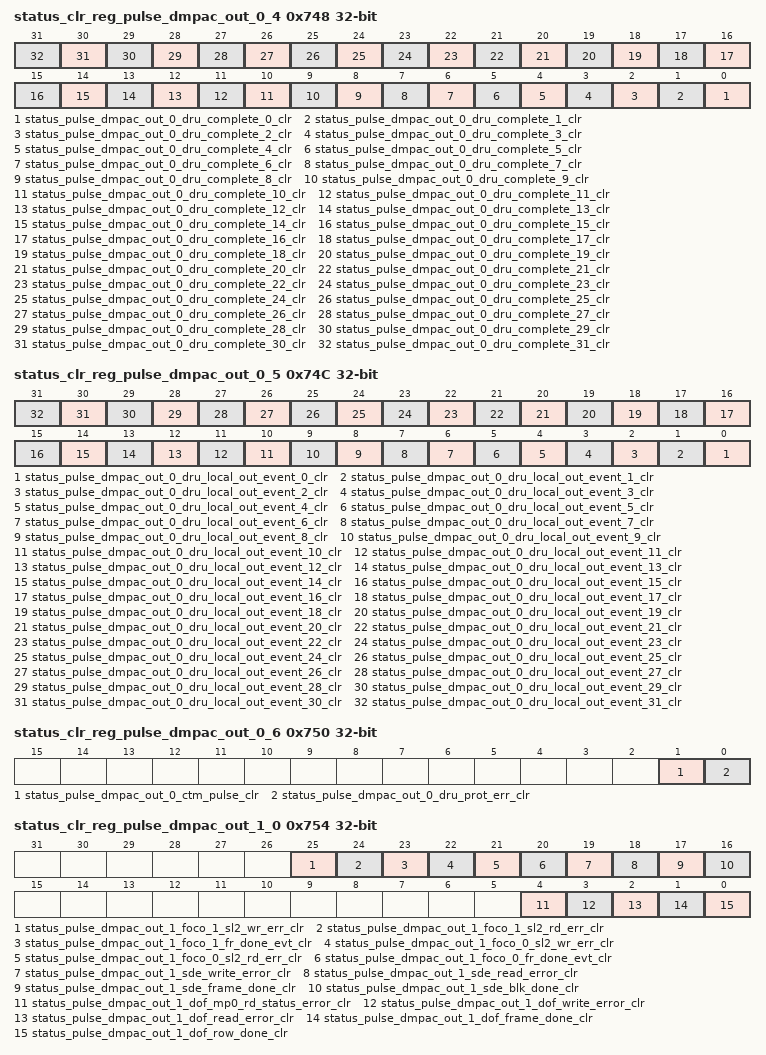
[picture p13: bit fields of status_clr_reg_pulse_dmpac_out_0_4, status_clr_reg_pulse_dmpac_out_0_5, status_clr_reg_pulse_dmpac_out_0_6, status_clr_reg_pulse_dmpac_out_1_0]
0x748 status_clr_reg_pulse_dmpac_out_0_4 — Status Clear Register 18
  [n] status_pulse_dmpac_out_0_dru_complete_{n}_clr (n=0..31) — Status ,write 1 to clear, for pulse_dmpac_out_0_en_dru_complete_{n}
{0x198+0x68*i} HWA{i}_cons0_control (i=14..19) — Controlling consumer socket 0 for HWA{i}
  [9:1] prod_select — producer select for HWA{i} cons socket 0
  [1:0] cons_en — '1' -> Consumer socket 0 enable , '0' Disable
0x74C status_clr_reg_pulse_dmpac_out_0_5 — Status Clear Register 19
  [n] status_pulse_dmpac_out_0_dru_local_out_event_{n}_clr (n=0..31) — Status ,write 1 to clear, for pulse_dmpac_out_0_en_dru_local_out_event_{n}
{0x19C+0x68*i} HWA{i}_cons1_control (i=14..19) — Controlling consumer socket 1 for HWA{i}
  [9:1] prod_select — producer select for HWA{i} cons socket 1
  [1:0] cons_en — '1' -> Consumer socket 1 enable , '0' Disable
0x750 status_clr_reg_pulse_dmpac_out_0_6 — Status Clear Register 20
  [1] status_pulse_dmpac_out_0_ctm_pulse_clr — Status ,write 1 to clear, for pulse_dmpac_out_0_en_ctm_pulse
  [0] status_pulse_dmpac_out_0_dru_prot_err_clr — Status ,write 1 to clear, for pulse_dmpac_out_0_en_dru_prot_err
{0x1A0+0x68*i} HWA{i}_prod0_control (i=14..19) — Controlling producer socket0 for HWA{i}
  [8:1] cons_select — consumer select for HWA{i} prod socket 0. Used in decrementing count of producer buffer
  [1:0] prod_en — '1' -> Producer socket 0 enable , '0' Disable
0x754 status_clr_reg_pulse_dmpac_out_1_0 — Status Clear Register 21
  [25] status_pulse_dmpac_out_1_foco_1_sl2_wr_err_clr — Status ,write 1 to clear, for pulse_dmpac_out_1_en_foco_1_sl2_wr_err
  [24] status_pulse_dmpac_out_1_foco_1_sl2_rd_err_clr — Status ,write 1 to clear, for pulse_dmpac_out_1_en_foco_1_sl2_rd_err
  [23] status_pulse_dmpac_out_1_foco_1_fr_done_evt_clr — Status ,write 1 to clear, for pulse_dmpac_out_1_en_foco_1_fr_done_evt
  [22] status_pulse_dmpac_out_1_foco_0_sl2_wr_err_clr — Status ,write 1 to clear, for pulse_dmpac_out_1_en_foco_0_sl2_wr_err
  [21] status_pulse_dmpac_out_1_foco_0_sl2_rd_err_clr — Status ,write 1 to clear, for pulse_dmpac_out_1_en_foco_0_sl2_rd_err
  [20] status_pulse_dmpac_out_1_foco_0_fr_done_evt_clr — Status ,write 1 to clear, for pulse_dmpac_out_1_en_foco_0_fr_done_evt
  [19] status_pulse_dmpac_out_1_sde_write_error_clr — Status ,write 1 to clear, for pulse_dmpac_out_1_en_sde_write_error
  [18] status_pulse_dmpac_out_1_sde_read_error_clr — Status ,write 1 to clear, for pulse_dmpac_out_1_en_sde_read_error
  [17] status_pulse_dmpac_out_1_sde_frame_done_clr — Status ,write 1 to clear, for pulse_dmpac_out_1_en_sde_frame_done
  [16] status_pulse_dmpac_out_1_sde_blk_done_clr — Status ,write 1 to clear, for pulse_dmpac_out_1_en_sde_blk_done
  [4] status_pulse_dmpac_out_1_dof_mp0_rd_status_error_clr — Status ,write 1 to clear, for pulse_dmpac_out_1_en_dof_mp0_rd_status_error
  [3] status_pulse_dmpac_out_1_dof_write_error_clr — Status ,write 1 to clear, for pulse_dmpac_out_1_en_dof_write_error
  [2] status_pulse_dmpac_out_1_dof_read_error_clr — Status ,write 1 to clear, for pulse_dmpac_out_1_en_dof_read_error
  [1] status_pulse_dmpac_out_1_dof_frame_done_clr — Status ,write 1 to clear, for pulse_dmpac_out_1_en_dof_frame_done
  [0] status_pulse_dmpac_out_1_dof_row_done_clr — Status ,write 1 to clear, for pulse_dmpac_out_1_en_dof_row_done
{0x1A4+0x68*i} HWA{i}_prod0_buf_control (i=14..19) — Controlling producer socket0 buffer for HWA{i}
  fields as HWA13_prod1_buf_control
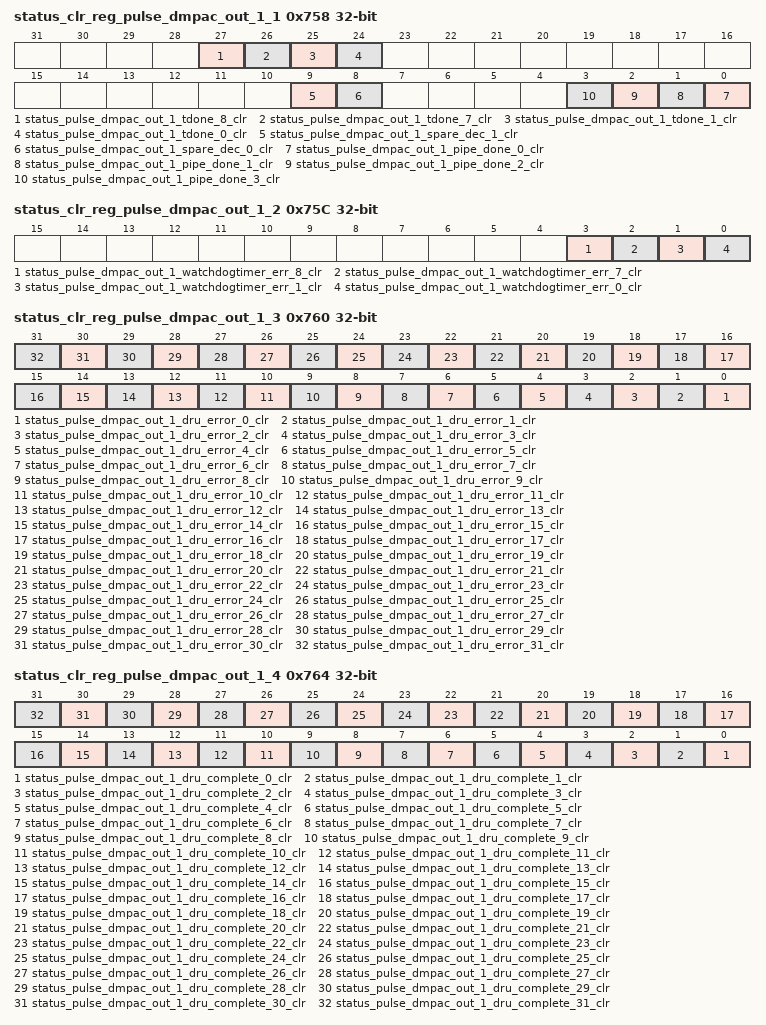
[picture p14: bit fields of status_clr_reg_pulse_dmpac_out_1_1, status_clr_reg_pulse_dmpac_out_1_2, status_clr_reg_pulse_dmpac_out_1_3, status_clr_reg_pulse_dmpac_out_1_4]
0x758 status_clr_reg_pulse_dmpac_out_1_1 — Status Clear Register 22
  [27] status_pulse_dmpac_out_1_tdone_8_clr — Status ,write 1 to clear, for pulse_dmpac_out_1_en_tdone_8
  [26] status_pulse_dmpac_out_1_tdone_7_clr — Status ,write 1 to clear, for pulse_dmpac_out_1_en_tdone_7
  [25] status_pulse_dmpac_out_1_tdone_1_clr — Status ,write 1 to clear, for pulse_dmpac_out_1_en_tdone_1
  [24] status_pulse_dmpac_out_1_tdone_0_clr — Status ,write 1 to clear, for pulse_dmpac_out_1_en_tdone_0
  [9] status_pulse_dmpac_out_1_spare_dec_1_clr — Status ,write 1 to clear, for pulse_dmpac_out_1_en_spare_dec_1
  [8] status_pulse_dmpac_out_1_spare_dec_0_clr — Status ,write 1 to clear, for pulse_dmpac_out_1_en_spare_dec_0
  [n] status_pulse_dmpac_out_1_pipe_done_{n}_clr (n=0..3) — Status ,write 1 to clear, for pulse_dmpac_out_1_en_pipe_done_{n}
{0x1A8+0x68*i} HWA{i}_prod0_count access per field (i=14..19) — Defining count values for pre/post load for generating pend by HWA{i} prod0
  fields as HWA13_prod1_count
0x75C status_clr_reg_pulse_dmpac_out_1_2 — Status Clear Register 23
  [3] status_pulse_dmpac_out_1_watchdogtimer_err_8_clr — Status ,write 1 to clear, for pulse_dmpac_out_1_en_watchdogtimer_err_8
  [2] status_pulse_dmpac_out_1_watchdogtimer_err_7_clr — Status ,write 1 to clear, for pulse_dmpac_out_1_en_watchdogtimer_err_7
  [1] status_pulse_dmpac_out_1_watchdogtimer_err_1_clr — Status ,write 1 to clear, for pulse_dmpac_out_1_en_watchdogtimer_err_1
  [0] status_pulse_dmpac_out_1_watchdogtimer_err_0_clr — Status ,write 1 to clear, for pulse_dmpac_out_1_en_watchdogtimer_err_0
0x760 status_clr_reg_pulse_dmpac_out_1_3 — Status Clear Register 24
  [n] status_pulse_dmpac_out_1_dru_error_{n}_clr (n=0..31) — Status ,write 1 to clear, for pulse_dmpac_out_1_en_dru_error_{n}
{0x760+0x14*i} HWA14_pa{i}_prodcount access per field (i=0..2) — count values for HWA14 prod socket{i}
  fields as HWA13_pa0_prodcount
0x764 status_clr_reg_pulse_dmpac_out_1_4 — Status Clear Register 25
  [n] status_pulse_dmpac_out_1_dru_complete_{n}_clr (n=0..31) — Status ,write 1 to clear, for pulse_dmpac_out_1_en_dru_complete_{n}
0x768 status_clr_reg_pulse_dmpac_out_1_5 — Status Clear Register 26
  [n] status_pulse_dmpac_out_1_dru_local_out_event_{n}_clr (n=0..31) — Status ,write 1 to clear, for pulse_dmpac_out_1_en_dru_local_out_event_{n}
0x76C status_clr_reg_pulse_dmpac_out_1_6 — Status Clear Register 27
  [1] status_pulse_dmpac_out_1_ctm_pulse_clr — Status ,write 1 to clear, for pulse_dmpac_out_1_en_ctm_pulse
  [0] status_pulse_dmpac_out_1_dru_prot_err_clr — Status ,write 1 to clear, for pulse_dmpac_out_1_en_dru_prot_err
{0x7C8+0x14*i} HWA15_pa{i}_prodcount access per field (i=0..2) — count values for HWA15 prod socket{i}
  fields as HWA13_pa0_prodcount
0x800 CTCNTL ro — Counter Timer Control
  [18:8] NUMINPT — Number of event input signals
  [7:6] NUMCNTR — Number of counters in the module
  [26:6] NUMSTM — Number of counters that can export via STM
  [13:5] NUMTIMR — Number of timers in the module
  [4:3] REVID — Revision ID of CTSET
  [1:0] NUMCOREMD — Indicated the number of mode bus interfaces, 0 is 2 CPU buses, 1 is 4 buses
0x800 SRB_S1_RAM ro — srb_s1_ram diagnostic read only port, vbusp will stall until RAM is available for read
  [24:8] rsvd — Always read as 0. Writes have no effect.
  [24:0] data — Data read from RAM
{0x800+0x20*i} intd_cfg_fw_region_{i}_control (i=0..3) — The FW Region {i} Control Register defines the control fields for the slave cp_intd.intd_cfg region {i} firewall.
  [4:1] lock — Lock region. Once set region values cannot be modified.
  [8:1] background — Background enable for region. There can be 1 backgroun region per FW and foreground regions can have overlapping addresses only with the background region.
  [9:1] cache_mode — Cache mode for region. Set to 1 to check cache permissions. Set to 0 to ignore cache permissions.
  [4:0] enable — Enable region. A value of 0xA enables, others disable.
0x804 CTNUMDBG ro — Counter Timer Number Debug Event Register
  [3:0] NUMEVT — Number of input selectors for debug events
{0x804+0x20*i} intd_cfg_fw_region_{i}_permission_0 (i=0..3) — The FW Region {i} Permission 0 Register defines the permissions for the slave cp_intd.intd_cfg region {i} firewall.
  [16:8] priv_id — Allowed privid.
  [1] sec_supv_read — Secure supervisor read allowed.
  [2:1] sec_supv_cacheable — Secure supervisor cacheable allowed.
  [3:1] sec_supv_debug — Secure supervisor debug allowed.
  [4:1] sec_user_write — Secure user write allowed.
  [5:1] sec_user_read — Secure user read allowed.
  [6:1] sec_user_cacheable — Secure user cacheable allowed.
  [7:1] sec_user_debug — Secure user debug allowed.
  [8:1] nonsec_supv_write — Non-secure supervisor write allowed.
  [9:1] nonsec_supv_read — Non-secure supervisor read allowed.
  [10:1] nonsec_supv_cacheable — Non-secure supervisor cacheable allowed.
  [11:1] nonsec_supv_debug — Non-secure supervisor debug allowed.
  [12:1] nonsec_user_write — Non-secure user write allowed.
  [13:1] nonsec_user_read — Non-secure user read allowed.
  [14:1] nonsec_user_cacheable — Non-secure user cacheable allowed.
  [15:1] nonsec_user_debug — Non-secure user debug allowed.
  [1:0] sec_supv_write — Secure supervisor write allowed.
0x808 CTUSERACCCTL access per field — Counter Timer User Access Control, can only be written in priviledged mode
  [1] RUSER rw — Counter functions while system is in Root-User mode
  [2:1] SECUSER rw — Counter functions while system is in Secure-User mode
  [1:0] NRUSER rw — Counter functions while system is in in Non-Root-User mode
{0x808+0x20*i} intd_cfg_fw_region_{i}_permission_1 (i=0..3) — The FW Region {i} Permission 1 Register defines the permissions for the slave cp_intd.intd_cfg region {i} firewall.
  fields as intd_cfg_fw_region_0_permission_0
{0x80C+0x20*i} intd_cfg_fw_region_{i}_permission_2 (i=0..3) — The FW Region {i} Permission 2 Register defines the permissions for the slave cp_intd.intd_cfg region {i} firewall.
  fields as intd_cfg_fw_region_0_permission_0
{0x810+0x20*i} intd_cfg_fw_region_{i}_start_address_l access per field (i=0..3) — The FW Region {i} Start Address Low Register defines the start address bits 31 to 0 for the slave cp_intd.intd_cfg region {i} firewall.
  [20:12] start_address_l rw — Start address bits 31 to 12. Lowest 12 bits are forced to 0 as address must be 4KB aligned.
  [12:0] start_address_lsb ro — Start address bits 11 to 0 are forced to 0 as address must be 4KB aligned.
{0x814+0x20*i} intd_cfg_fw_region_{i}_start_address_h (i=0..3) — The FW Region {i} Start Address High Register defines the start address bits 47 to 32 for the slave cp_intd.intd_cfg region {i} firewall.
  [16:0] start_address_h — Start address bits 47 to 32.
{0x818+0x20*i} intd_cfg_fw_region_{i}_end_address_l access per field (i=0..3) — The FW Region {i} End Address Low Register defines the end address bits 31 to 0 to include for the slave cp_intd.intd_cfg region {i} firewall.
  [20:12] end_address_l rw — End address bits 31 to 12 to include in the match. Lowest 12 bits are forced to 1s as address must be 4KB aligned.
  [12:0] end_address_lsb ro — End address bits 11 to 0 are forced to 1s as address must be 4KB aligned minus 1.
{0x81C+0x20*i} intd_cfg_fw_region_{i}_end_address_h (i=0..3) — The FW Region {i} End Address High Register defines the end address bits 47 to 32 to include for the slave cp_intd.intd_cfg region {i} firewall.
  [16:0] end_address_h — End address bits 47 to 32 to include in the match.
0x820 CTSTMCNTL access per field — Counter Timer STM Control register
  [6] NUMXPORT ro — The total number of counters designated for export
  [1] SENDOVR rw — Send overflow data in CSM frame
  [2:1] CSMXPORT rw — SW control of CSM message export
  [3:1] CCMAVAIL rw — CTSET supports CCM export
  [4:1] CCMPORT rw — SW control of CCM message export
  [5:1] XPORTACT ro — Indicates if a frame is currently being written to the STM.
  [1:0] ENBL rw — CTSET STM global enable for counter/timer messages
0x824 CTSTMMSTID access per field — Counter Timer STM Master ID register
  [8:0] MASTID rw — HW Master ID for System Event module
0x828 CTSTMINTVL access per field — Counter Timer STM Interval Register
  [15:0] INTERVAL rw — Counter Timer Periodic export interval
0x82C CTSTMSEL0 — Counter Timer STM Counter Select Register 0. This Selects Counter 0 to 31
  [32:0] COUNTSEL — The individual bit is this field indicate whether the corresponding counter value is included in the CSM message generated via the STM interface
{0x830+0x14*i} HWA16_pa{i}_prodcount access per field (i=0..2) — count values for HWA16 prod socket{i}
  fields as HWA13_pa0_prodcount
0x830 CTSTMSEL1 — Counter Timer STM Counter Select Register 1. This Selects Counter 32 to 63
  fields as CTSTMSEL0
{0x840+4i} CTINTVLR{i} (i=0..15) — These registers contain the interval match value for the corresponding timers in the CTSET. TINTVLRn are available based on number of timers instantiated.
  [32:0] INTERVAL — Interval match value for the timers in the CTSET
{0x898+0x14*i} HWA17_pa{i}_prodcount access per field (i=0..2) — count values for HWA17 prod socket{i}
  fields as HWA13_pa0_prodcount
0x8A0 CTDBGSGL0 access per field — Timer Interval Register 0. Interval match value for timer 0 in CTSET Timer Interval Register 1. Interval match value for timer 1 in CTSET Timer Interval Register 2. Interval match value for timer 2 in CTSET Timer Interval Register 3. Interval match value for timer 3 in CTSET Timer Interval Register 4. Interval match value for timer 4 in CTSET Timer Interval Register 5. Interval match value for timer 5 in CTSET Timer Interval Register 6. Interval match value for timer 6 in CTSET Timer Interval Register 7. Interval match value for timer 7 in CTSET Timer Interval Register 8. Interval match value for timer 8 in CTSET Timer Interval Register 9. Interval match value for timer 9 in CTSET Timer Interval Register 10. Interval match value for timer 10 in CTSET Timer Interval Register 11. Interval match value for timer 11 in CTSET Timer Interval Register 12. Interval match value for timer 12 in CTSET Timer Interval Register 13. Interval match value for timer 13 in CTSET Timer Interval Register 14. Interval match value for timer 14 in CTSET Timer Interval Register 15. Interval match value for timer 15 in CTSET Counter Timer Debug Event Register 0
  [8:0] INPSEL rw — Counter Timer input selection
{0x8A0+4i} CTDBGSGL{i} access per field (i=1..4) — Counter Timer Debug Event Register {i}
  [8:0] INPSEL rw — Counter Timer input selection
0x8B4 CTDBGSGL5 access per field — Counter Timer Debug Event Register5
  [8:0] INPSEL rw — Counter Timer input selection
0x8B8 CTDBGSGL6 access per field — Counter Timer Debug Event Register 6
  [8:0] INPSEL rw — Counter Timer input selection
0x8BC CTDBGSGL7 access per field — Counter Timer Debug Event Register 7
  [8:0] INPSEL rw — Counter Timer input selection
{0x900+0x14*i} HWA18_pa{i}_prodcount access per field (i=0..2) — count values for HWA18 prod socket{i}
  fields as HWA13_pa0_prodcount
{0x968+0x14*i} HWA19_pa{i}_prodcount access per field (i=0..2) — count values for HWA19 prod socket{i}
  fields as HWA13_pa0_prodcount
{0x9A8+0x1C*i} DMA{i}_scheduler_control access per field (i=0..4) — Scheduler Control Register
  [13:8] dma_channel_no rw — DMA channel number for thread scheduler for DMA{i}
  [7:4] state ro — Current state of DMA{i} Scheduler
  [3:1] pipeline_num rw — Pipeline Number of DMA{i} Scheduler
  [5:1] strm_en rw — '1' -> Streaming input enable, '0' No streaming input
  [6:1] pause rw — '1' -> pause/suspend scheduler , '0' -> resume scheduler
  [12:1] debug_rdy rw — '0' -> DMA{i} Scheduler resources must not be read during halted state. '1'-> DMA{i} Scheduler resources are readable during halted state
  [1:0] sch_en rw — scheduler enable; write '1' to enable scheduler
{0x9AC+0x1C*i} DMA{i}_HOP (i=0..4) — Scheduler HOP Control Register. Help in detecting eop within scheduler. Once configured, it counts task/channel starts and stops issuing further starts. Specifically useful for Head of pipe dma scheduler .
  fields as HWA14_HOP
{0x9B8+0x1C*i} DMA{i}_prod0_control (i=0..4) — Controlling producer socket0 for DMA{i}
  [8:1] cons_select — consumer select for DMA{i} prod socket 0. Used in decrementing count of producer buffer
  [1:0] prod_en — '1' -> Producer socket 0 enable , '0' Disable
{0x9BC+0x1C*i} DMA{i}_prod0_buf_control (i=0..4) — Controlling producer socket0 buffer for DMA{i}
  fields as HWA13_prod1_buf_control
{0x9C0+0x1C*i} DMA{i}_prod0_count access per field (i=0..4) — Defining count values for pre/post load for generating pend by DMA{i} prod0
  fields as HWA13_prod1_count
0x9F0 CTGNBL0 — Counter Timer Global Enable Register 0. This enables Counter 0 to 31
  [8:0] ENABLE — The individual bit is this field enables the corresponding counter. Bits 30 and 31 will be high if global time stamp output interface is enabled
0x9F4 CTGNBL1 — Counter Timer Global Enable Register 1. This enables Counter 32 to 63
  [8:0] ENABLE — The individual bit is this field enables the corresponding counter
0x9F8 CTGRST0 — Counter Timer Global Reset Register 0. This resets Counter 0 to 31
  [8:0] RESET — The individual bit is this field resets the corresponding counter. These bits are self-clearing, once a '1' is written, after the counters are reset these bits are cleared. When Global Time Stamp output interface is enabled, counter 31 and counter 30 should not be written to any value
0x9FC CTGRST1 — Counter Timer Global Reset Register 0. This resets Counter 32 to 63
  [8:0] RESET — The individual bit is this field resets the corresponding counter. These bits are self-clearing, once a '1' is written, after the counters are reset these bits are cleared.
{0xA00+4i} CTCR{i} access per field (i=0..31) — Counter Timer Control Register {i}
  [16:8] INPSEL rw — Counter Timer input selection. For WD mode it is the start event selector
  [24:8] WDRESET rw — WD reset event input selector. Only available for modules capable of timer and counter functions. This bit is reserved (read only) for counter registers which are only counter function
  [14:2] MODESEL rw — Counter is in duration or occurrence mode. Only writable by debug accesses
  [1] RESET rw — Counter reset control
  [2:1] CHAIN rw — Counter is chained to an adjacent counter
  [3:1] DURMODE rw — Counter is in duration or occurrence mode
  [6:1] OVRFLW rw — Counter is in duration or occurrence mode
  [7:1] CHNSDW rw — Counter has a shadow register for chain reads. Only valid on counters with an even number index
  [8:1] INT rw — Generate interrupt on interval match. Only available for modules capable of timer and counter functions. This bit is reserved (read only) for counter registers which are only counter function
  [9:1] DBG rw — Signal debug logic on interval match. Only available for modules capable of timer and counter functions. This bit is reserved (read only) for counter registers which are only counter function
  [10:1] RESTART rw — Restart the timer after an interval match. Only available for modules capable of timer and counter functions. This bit is reserved (read only) for counter registers which are only counter function
  [11:1] WDMODE rw — WD Timer mode selection. Only available for modules capable of timer and counter functions. This bit is reserved (read only) for counter registers which are only counter function
  [12:1] DBG_TRIG_STAT rw — Debug event triggered. Write 1 will clear this bit. Only available for modules capable of timer and counter functions. This bit is reserved (read only) for counter registers which are only counter function
  [13:1] FILTER rw — Use associated operating mode filter in CTMODEFILTERn
  [1:0] ENBL rw — Counter enable control
